# pse84 register map
Vendor: Infineon Technologies; Series: PSE84; File version: 1.0
CPU: CM33 r0p1, little endian, MPU, FPU, VTOR, 3 interrupt priority bits
Registers are 32-bit, read-write, reset 0x0 unless marked. A register's access mark holds for its fields unless they carry their own. Offsets are from the block's base; [hi:lo] are bit positions; lines under a group give offsets from that group; {n}, {i} and the like mark numbered series; 'fields as' and 'values as' point back to an identical list; <NAME> marks a mode.

## SRSS (part 2 of 3) — SRSS Core Registers
Base 0x42400000
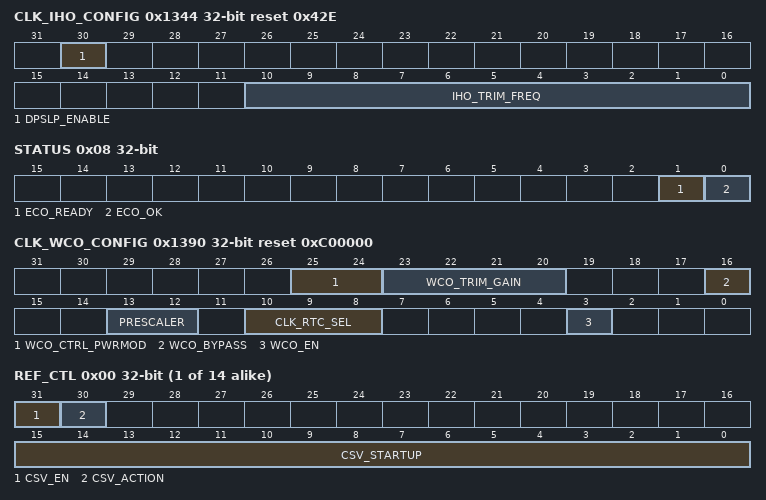
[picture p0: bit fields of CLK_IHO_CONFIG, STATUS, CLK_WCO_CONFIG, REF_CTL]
0x1344 CLK_IHO_CONFIG reset 0x42E — IHO Configuration Register
  [30] DPSLP_ENABLE — Enable for IHO during DEEPSLEEP. This bit configures IHO behavior during DEEPSLEEP: 0: IHO is automatically disabled during DEEPSLEEP and enables upon wakeup; 1: IHO is kept enabled throughout DEEPSLEEP
  [10:0] IHO_TRIM_FREQ — IHO frequency trim
0x1360 CLK_ECO group — ECO Configuration
  0x00 CONFIG — ECO Configuration Register
    [31] ECO_EN — Master enable for ECO oscillator. Configure the settings in CLK_ECO_CONFIG2 to work with the selected crystal, before enabling ECO.
    [28] ECO_DIV_ENABLE — ECO prescaler enable command (mutually exclusive with ECO_DIV_DISABLE). ECO Prescaler only works in ACTIVE and SLEEP modes. SW sets this field to '1' to enable the divider and HW sets this field to '0' to indicate that divider enabling has completed. When the divider is enabled, its integer and fractional counters are initialized to '0'. If a divider is to be re-enabled using different integer and fractional divider values, the SW should follow these steps: 0: Disable the divider using the ECO_DIV_DISABLE field. 1: Configure CLK_ECO_PRESCALE registers. 2: Enable the divider using the ECO_DIV_ENABLE field. HW sets the ECO_DIV_ENABLE field to '0' when the enabling is performed and HW set CLK_ECO_PRESCALER.ENABLED to '1' when the enabling is performed.
    [27] ECO_DIV_DISABLE — ECO prescaler disable command (mutually exclusive with ECO_DIV_ENABLE). SW sets this field to '1' and HW sets this field to '0'. HW sets ECO_DIV_DISABLE field to '0' immediately and HW sets CLK_ECO_PRESCALE.ECO_DIV_EN field to '0' immediately.
  0x04 CONFIG2 reset 0x61B — ECO Configuration Register 2
    [16] ECO_CTRL_AMPDETEN — Amplifer detect enable
    [11:8] ECO_TRIM_GAIN — Gain trim
    [4:0] ECO_TRIM_CL — Crystal load cap configuration trim
  0x08 STATUS ro — ECO Status Register
    [1] ECO_READY — Indicates the ECO internal oscillator circuit power has had enough time to fully stabilize and the CLK_EN can be set. The ECO_OK bit should be used to determine that the ECO is ready for use.
    [0] ECO_OK — Indicates the ECO internal oscillator circuit has sufficient amplitude. It may not meet the PPM accuracy or duty cycle spec.
0x1370 CLK_PILO_CONFIG reset 0x80000000 — Precision ILO Configuration Register
  [31] PILO_EN — Enable PILO. If the PILO is the selected source for WDT, writes to this field are ignored unless the WDT is unlocked using WDT_LOCK register. To save power FW must disable PILO upon entry to Hibernate if it is not used as a Hibernate clock source. PILO will continue to run in XRES if enabled.
0x1374 CLK_PILO_STATUS ro — Precision ILO Status Register
  [0] PILO_OK — Indicates the PILO is running.
0x1380 CLK_ILO_CONFIG reset 0x80000000 — ILO Configuration
  [31] ENABLE — Enable ILO. If the ILO is the selected source for WDT, writes to this field are ignored unless the WDT is unlocked using WDT_LOCK register. To save power, FW must disable ILO upon entry to Hibernate if it is not used as a Hibernate clock source. ILO will continue to run in XRES if enabled.
0x1384 CLK_TRIM_ILO_CTL reset 0x2C — ILO Trim Register
  [5:0] ILO_FTRIM — IL0 frequency trims. LSB step size is 1.5 percent (typical) of the frequency. If the ILO is the selected source for WDT, writes to this field are ignored unless the WDT is unlocked using WDT_LOCK register.
0x1390 CLK_WCO_CONFIG reset 0xC00000 — WCO Configuration Register
  [25:24] WCO_CTRL_PWRMOD
  [23:20] WCO_TRIM_GAIN — main amplifier gain control. Please use S22SRSSA_WCO_CALCULATOR to obtain appropriate value for the attached crystal. Writes to this field are ignored unless the WDT is unlocked using WDT_LOCK register
  [16] WCO_BYPASS — Configures the WCO for different board-level connections to the WCO pins. For example, this can be used to connect an external watch crystal oscillator instead of a watch crystal. In all cases, the two related GPIO pins (WCO input and output pins) must be configured as analog connections using GPIO registers, and they must be hooked at the board level as described below. Configure this field before enabling the WCO, and do not change this setting when WCO_EN=1. Also if the BAK (RTC) is the selected source for WDT, Writes to this field are ignored unless the WDT is unlocked using WDT_LOCK register. 0: Watch crystal. Connect a 32.768 kHz watch crystal between WCO input and output pins. 1: Clock signal, either a square wave or sine wave. See PRESCALER field for connection information.
  [13:12] PRESCALER
  [10:8] CLK_RTC_SEL — Clock select for RTC clock. If the BAK (RTC) is the selected source for WDT, Writes to this field are ignored unless the WDT is unlocked using WDT_LOCK register. Selecting a clock that is not running results in unpredictable behavior.
    0=WCO (Watch-crystal oscillator input, available in Active, DeepSleep and Hibernate.); 1=ALTBAK (This allows to use the LFCLK selection as an alternate backup domain clock. Note that LFCLK is only available in Active and DeepSleep power modes. Note that LFCLK clock glitches can propagate into the RTC logic when the clock is stopped. For this reason, if the WCO, PILO or ILO is intended as the clock source then choose it directly instead of routing through LFCLK.); 2=ILO (Internal Low frequency Oscillator, available in Active, DeepSleep, and Hibernate. With this option selected, ILO reset is suppressed in XRES/Hibernate modes.); 3=PILO (Precision internal low-speed oscillator, available in Active, DeepSleep, and Hibernate. With this option selected, PILO reset is suppressed in XRES/Hibernate modes.); 4=RSVD (N/A)
  [3] WCO_EN — Watch-crystal oscillator (WCO) enable. If there is an RTC write in progress and WCO is the clock source for clk_rtc when this bit is cleared, the WCO will be internally kept on until the write completes. After enabling the WCO software must wait until CLK_WCO_STATUS.WCO_OK=1 before configuring any component that depends on clk_lf/clk_rtc, like for example RTC or WDTs. If the BAK (RTC) is the selected source for WDT, writes to this field are ignored unless the WDT is unlocked using WDT_LOCK register.
0x1394 CLK_WCO_STATUS ro — WCO Status Register
  [2] WCO_OK — Indicates that output has transitioned.
0x1400 CSV_HF group — Clock Supervisor (CSV) registers for Root clocks
  {0x0+0x10*j} CSV[{j}] (j=0..13) group — Active domain Clock Supervisor (CSV) registers
    0x00 REF_CTL — Clock Supervision Reference Control
      [31] CSV_EN — Enables clock supervision, both frequency and loss. CSV in Active domain: Clock supervision is reset during DeepSleep and Hibernate modes. When enabled it begins operating automatically after a DeepSleep wakeup, but it must be reconfigured after Hibernate wakeup. CSV in DeepSleep domain: Clock supervision is reset during Hibernate mode. It must be reconfigured after Hibernate wakeup. A CSV error detection is reported to the Fault structure, or instead it can generate a power reset.
      [30] CSV_ACTION — Specifies the action taken when an anomaly is detected on the monitored clock. CSV in DeepSleep domain always do a Fault report (which also wakes up the system).
        0=FAULT (Generate a fault); 1=RESET (Cause a power reset. This should only be used for clk_hf0.)
      [15:0] CSV_STARTUP — Startup delay time -1 (in reference clock cycles), after enable or DeepSleep wakeup, from reference clock start to monitored clock start. At a minimum (both clocks running): STARTUP >= (PERIOD +3) * FREQ_RATIO - UPPER, with FREQ_RATIO = (Reference frequency / Monitored frequency) On top of that the actual clock startup delay and the margin for accuracy of both clocks must be added.
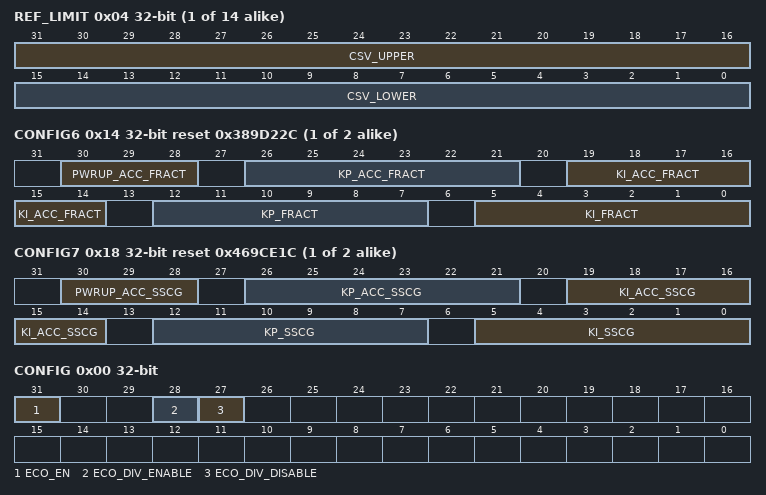
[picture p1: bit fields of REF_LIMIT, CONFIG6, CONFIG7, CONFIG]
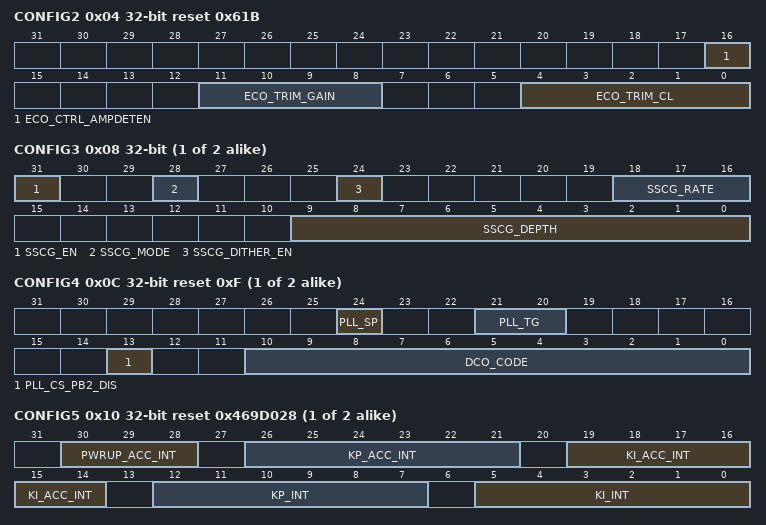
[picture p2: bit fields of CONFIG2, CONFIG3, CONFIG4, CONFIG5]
    0x04 REF_LIMIT — Clock Supervision Reference Limits
      [31:16] CSV_UPPER — Cycle time upper limit. Set the upper limit -1, in reference clock cycles, before (or same time) the next monitored clock event must happen. If a monitored clock event does not happen before this limit is reached, or does not happen at all (clock loss), a CSV error is detected.
      [15:0] CSV_LOWER — Cycle time lower limit. Set the lower limit -1, in reference clock cycles, before the next monitored clock event is allowed to happen. If a monitored clock event happens before this limit is reached a CSV error is detected. LOWER must be at least 1 less than UPPER. In case the clocks are asynchronous LOWER must be at least 3 less than UPPER.
    0x08 MON_CTL — Clock Supervision Monitor Control
      [15:0] CSV_PERIOD — Period time. Set the Period -1, in monitored clock cycles, before the next monitored clock event happens. PERIOD <= (UPPER+1) / FREQ_RATIO -1, with FREQ_RATIO = (Reference frequency / Monitored frequency) In case the clocks are asynchronous: PERIOD <= UPPER / FREQ_RATIO -1 Additionally margin must be added for accuracy of both clocks.
0x1500 CSV_REF_SEL reset 0x4 — Select CSV Reference clock for Active domain
  [2:0] REF_MUX — Selects a source for clock clk_ref_hf. Note that not all products support all clock sources. Selecting a clock source that is not supported will result in undefined behavior. It takes four cycles of the originally selected clock to switch away from it. Do not disable the original clock during this time.
    0=IMO (IMO - Internal R/C Oscillator (product specific)); 1=EXTCLK (EXTCLK - External Clock Pin); 2=ECO (ECO - External-Crystal Oscillator); 3=ALTHF0 (ALTHF0 - Alternate High-Frequency clock input (product-specific clock)); 4=IHO (IHO - Internal High-speed Oscillator); 5=ALTHF1 (ALTHF1 - Alternate High-Frequency clock input (product-specific clock))
0x1510 CSV_REF group — CSV registers for the CSV Reference clock
  0x00 CSV group — Active domain Clock Supervisor (CSV) registers for CSV Reference clock
    0x00 REF_CTL — Clock Supervision Reference Control
      fields as CSV_HF.CSV[0].REF_CTL
    0x04 REF_LIMIT — Clock Supervision Reference Limits
      fields as CSV_HF.CSV[0].REF_LIMIT
    0x08 MON_CTL — Clock Supervision Monitor Control
      fields as CSV_HF.CSV[0].MON_CTL
0x1520 CSV_LF_REF_SEL — Select CSV Reference clock for LF clock
  [1:0] LF_REF_MUX — Selects a source for clock clk_ref_lf. Note that not all products support all clock sources. Selecting a clock source that is not supported will result in undefined behavior. It takes four cycles of the originally selected clock to switch away from it. Do not disable the original clock during this time. Same clcok sources are also souce for clk_lf. Do not select the same clock.
    0=PILO (Precision internal low-speed oscillator, available in Active, DeepSleep, and Hibernate. (Product Specific)); 1=ILO (Internal Low frequency Oscillator, available in Active, DeepSleep, and Hibernate. (Product Specific)); 2=WCO (Watch-crystal oscillator input, available in Active, DeepSleep, and Hibernate. (Product Specific)); 3=TIMERCLK (Timer clock. Divided clock from IHO set to 1MHz. Available only during Active mode. If this clock is selected as reference, CSV will be disabled by hardware when entering lower power modes (DPSLP) and re-enabled back in Active.)
0x1530 CSV_LF group — CSV registers for LF clock
  0x00 CSV group — LF clock Clock Supervisor registers
    0x00 REF_CTL — Clock Supervision Reference Control
      [31] CSV_EN — Enables clock supervision, both frequency and loss. CSV in Active domain: Clock supervision is reset during DeepSleep and Hibernate modes. When enabled it begins operating automatically after a DeepSleep wakeup, but it must be reconfigured after Hibernate wakeup. CSV in DeepSleep domain: Clock supervision is reset during Hibernate mode. It must be reconfigured after Hibernate wakeup. CSV in Backup domain: Clock supervision operates during Hibernate mode, can be configured to wake from Hibernate, and continues operating during reboot. A CSV error detection is reported to the Fault structure.
      [7:0] CSV_STARTUP — Startup delay time -1 (in reference clock cycles), after enable, from reference clock start to monitored clock start. At a minimum (both clocks running): STARTUP >= (PERIOD +3) * FREQ_RATIO - UPPER, with FREQ_RATIO = (Reference frequency / Monitored frequency) On top of that the actual clock startup delay and the margin for accuracy of both clocks must be added.
    0x04 REF_LIMIT — Clock Supervision Reference Limits
      [23:16] CSV_UPPER — Cycle time upper limit. Set the upper limit -1, in reference clock cycles, before (or same time) the next monitored clock event must happen. If a monitored clock event does not happen before this limit is reached, or does not happen at all (clock loss), a CSV error is detected.
      [7:0] CSV_LOWER — Cycle time lower limit. Set the lower limit -1, in reference clock cycles, before the next monitored clock event is allowed to happen. If a monitored clock event happens before this limit is reached a CSV error is detected. LOWER must be at least 1 less than UPPER. In case the clocks are asynchronous LOWER must be at least 3 less than UPPER.
    0x08 MON_CTL — Clock Supervision Monitor Control
      [7:0] CSV_PERIOD — Period time. Set the Period -1, in monitored clock cycles, before the next monitored clock event happens. PERIOD <= (UPPER+1) / FREQ_RATIO -1, with FREQ_RATIO = (Reference frequency / Monitored frequency) In case the clocks are asynchronous: PERIOD <= UPPER / FREQ_RATIO -1 Additionally margin must be added for accuracy of both clocks.
0x1540 CSV_PILO_REF_SEL — Select CSV Reference clock for PILO clock
  [1:0] PILO_REF_MUX — Selects a source for clock clk_ref_pilo. Note that not all products support all clock sources. Selecting a clock source that is not supported will result in undefined behavior. It takes four cycles of the originally selected clock to switch away from it. Do not disable the original clock during this time. PILO is a source for clk_lf. Do not select LF when LF clock is using PILO.
    0=LFCLK (Root of the low-speed clock tree (LFCLK)); 1=ILO (Internal Low frequency Oscillator, available in Active, DeepSleep, and Hibernate. (Product Specific)); 2=WCO (Watch-crystal oscillator input, available in Active, DeepSleep, and Hibernate. (Product Specific)); 3=TIMERCLK (Timer clock. Divided clock from IHO set to 1MHz. Available only during Active mode. If this clock is selected as reference, CSV will be disabled by hardware when entering lower power modes (DPSLP) and re-enabled back in Active.)
{0x1600+0x20*i} CLK_DPLL_LP[{i}] (i=0..1) group — DPLL LP Configuration Register
  0x00 CONFIG reset 0x20116 — DPLL_LP Configuration Register
    [31] ENABLE — Master enable for PLL. Setup FEEDBACK_DIV, REFERENCE_DIV, and OUTPUT_DIV at least one cycle before setting ENABLE=1. fOUT = (FEEDBACK_DIV + FRAC_EN*FRAC_DIV/2^24) * (fREF / REFERENCE_DIV) / (OUTPUT_DIV) 0: Block is disabled. When the PLL disables, hardware controls the bypass mux as described in BYPASS_SEL, before disabling the PLL circuit. 1: Block is enabled
    [29:28] BYPASS_SEL — Bypass mux located just after PLL output. This selection is glitch-free and can be changed while the PLL is running. When changing BYPASS_SEL, do not turn off the reference clock or PLL clock for five cycles (whichever is slower).
      0=AUTO (Automatic using lock indicator. When unlocked, automatically selects PLL reference input (bypass mode). When locked, automatically selects PLL output. If ENABLE=0, automatically selects PLL reference input.); 1=LOCKED_OR_NOTHING (Similar to AUTO, except the clock is gated off when unlocked. This is compatible with clock supervision, because the supervisors allow no clock during startup (until a timeout occurs), and the clock targets the proper frequency whenever it is running. If ENABLE=0, no clock is output.); 2=PLL_BYPASS (Select PLL reference input (bypass mode). Ignores lock indicator); 3=PLL_OUT (Select PLL output. Ignores lock indicator. If ENABLE=0, no clock is output.)
    [27] PLL_DCO_MODE — dco_mode='0' DCO freq 160-310MHz , '1' - DCO freq 310-480MHz
    [20:16] OUTPUT_DIV — Control bits for Output divider. Set the divide value before enabling the PLL, and do not change it while PLL is enabled. 0: illegal (undefined behavior) 1: divide by 1. Suitable for direct usage as HFCLK source. 2: divide by 2. Suitable for direct usage as HFCLK source. ... 16: divide by 16. Suitable for direct usage as HFCLK source. >16: illegal (undefined behavior)
    [12:8] REFERENCE_DIV — Control bits for reference divider. Set the divide value before enabling the PLL, and do not change it while PLL is enabled. 0: illegal (undefined behavior) 1: divide by 1 ... 16: divide by 16 others: illegal (undefined behavior)
    [7:0] FEEDBACK_DIV — Control bits for feedback divider. Set the divide value before enabling the PLL, and do not change it while PLL is enabled. 0-15: illegal (undefined behavior) 16: divide by 16 ... 200: divide by 200 >200: illegal (undefined behavior)
  0x04 CONFIG2 — DPLL_LP Configuration Register 2
    [31] FRAC_EN — Enables fractional division mode.
    [30:28] FRAC_DITHER_EN
    [23:0] FRAC_DIV — Control bits for fractional divider. This value is interpreted as a fraction of the PFD frequency, i.e. fPFD * (FRAC_DIV/2^24). This field can be dynamically updated within the 1000ppm control limit. It takes up to 115 AHB cycles to transfer the setting to the PLL, and writes that occur faster may be silently ignored and require the application to write again after the previous update has finished. Reading the register returns the accepted value. The PLL will start targeting the new value, but it may take significant time (milliseconds) to stabilize at the new average value. Do not change the FRAC_DIV setting while the PLL is initially locking.
  0x08 CONFIG3 — DPLL_LP Configuration Register 3
    [31] SSCG_EN — Enables spreading mode. When SSCG mode is enabled, DPLL_LP_TEST4.PLL_DIS_FAST_LOCK should be set to 1 to disable fast re-lock.
    [28] SSCG_MODE
    [24] SSCG_DITHER_EN
    [18:16] SSCG_RATE
    [9:0] SSCG_DEPTH
  0x0C CONFIG4 reset 0xF — DPLL_LP Configuration Register 4
    [24] PLL_SP
    [21:20] PLL_TG — This value is a number of PFD clocks in relation to the DCO count. Can change the number of counts, set by p_div in integer mode, by the values of -1, +1, or +2. 0: 0 1: -1 2: +1 3: +2 In integer and SSCG mode, PLL_TG must be set to 0. If in fractional mode, PLL_TG must be 0 if frac_ratio <= 0.5 (pll_frac <= 2^23), PLL_TG must be 2 if frac_ratio > 0.5 (pll_frac > 2^23).
    [13] PLL_CS_PB2_DIS — disable internal bias
    [10:0] DCO_CODE — Initial DCO code. It is recommended to leave this at the default setting. This setting only has effect in open loop mode. See DPLL BROS regarding test modes.
  0x10 CONFIG5 reset 0x469D028 — DPLL_LP Configuration Register 5
    [30:28] PWRUP_ACC_INT — Power Up Accleration Coefficient for INT operation
    [26:21] KP_ACC_INT — Gain of P/I loop filter integrator path during cold start for INT operation. Gain coefficient is 2^KP, eg. 0=>1, 15=>32768.
    [19:14] KI_ACC_INT — Gain of P/I loop filter integrator path during cold start for INT operation. Gain coefficient is 2^KI, eg. 0=>1, 15=>32768.
    [12:7] KP_INT — Gain of P/I loop filter integrator path for INT operation. Gain coefficient is 2^KP, eg. 0=>1, 15=>32768.
    [5:0] KI_INT — Gain of P/I loop filter integrator path for INT operation. Gain coefficient is 2^KI, eg. 0=>1, 15=>32768.
  0x14 CONFIG6 reset 0x389D22C — DPLL_LP Configuration Register 6
    [30:28] PWRUP_ACC_FRACT — Power Up Accleration Coefficient for FRACT operation
    [26:21] KP_ACC_FRACT — Gain of P/I loop filter integrator path during cold start for FRACT operation. Gain coefficient is 2^KP, eg. 0=>1, 15=>32768.
    [19:14] KI_ACC_FRACT — Gain of P/I loop filter integrator path during cold start for FRACT operation. Gain coefficient is 2^KI, eg. 0=>1, 15=>32768.
    [12:7] KP_FRACT — Gain of P/I loop filter proportional path for FRACT operation. Gain coefficient is 2^KP, eg. 0=>1, 15=>32768.
    [5:0] KI_FRACT — Gain of P/I loop filter proportional path for FRACT operation. Gain coefficient is 2^KI, eg. 0=>1, 15=>32768.
  0x18 CONFIG7 reset 0x469CE1C — DPLL_LP Configuration Register 7
    [30:28] PWRUP_ACC_SSCG — Power Up Accleration Coefficient for SSCG operation
    [26:21] KP_ACC_SSCG — Gain of P/I loop filter integrator path during cold start for SSCG operation. Gain coefficient is 2^KP, eg. 0=>1, 15=>32768.
    [19:14] KI_ACC_SSCG — Gain of P/I loop filter integrator path during cold start for SSCG operation. Gain coefficient is 2^KI, eg. 0=>1, 15=>32768.
    [12:7] KP_SSCG — Gain of P/I loop filter proportional path for SSCG operation. Gain coefficient is 2^KP, eg. 0=>1, 15=>32768.
    [5:0] KI_SSCG — Gain of P/I loop filter proportional path for SSCG operation. Gain coefficient is 2^KI, eg. 0=>1, 15=>32768.
  0x1C STATUS — DPLL_LP Status Register
    [1] UNLOCK_OCCURRED — This bit sets whenever the PLL Lock bit goes low, and stays set until cleared by firmware. Note: When disabling DPLL via register write, UNLOCK_OCCURRED will set. Therefore, after enabling DPLL and DPLL successfully locks, FW should clear UNLOCK_OCCURRED flag to prevent a false positive that would indicate that DPLL erroneously unlocked.
    [0] LOCKED ro — PLL Lock Indicator
0x1800 CLK_DPLL_HP group — DPLL HP Configuration Register
  0x00 CONFIG reset 0x1013 — DPLL_HP Configuration Register
    [31] ENABLE — Master enable for PLL. Setup PLL for integer, fract or SCSG at least one cycle before setting ENABLE=1. 0: Block is disabled. When the PLL disables, hardware controls the bypass mux as described in BYPASS_SEL, before disabling the PLL circuit. 1: Block is enabled
    [29:28] BYPASS_SEL — Bypass mux located just after PLL output. This selection is glitch-free and can be changed while the PLL is running. When changing BYPASS_SEL, do not turn off the reference clock or PLL clock for five cycles (whichever is slower).
      values as CLK_DPLL_LP[0].CONFIG.BYPASS_SEL
    [14:12] PLL_FREQ_KDIV_SEL — K-divider division factor (K = kdiv_sel_i + 1 )
    [10:8] PLL_FREQ_PDIV_SEL — P-divider division factor (P = pdiv_sel_i + 1 ) (Cannot be changed on the fly when the PLL is enabled)
    [7:0] PLL_FREQ_NDIV_INT_SEL — N-divider division factor (N = ndiv_sel_i + 1 ) (Cannot be changed on the fly when the PLL is enabled)
  0x04 CONFIG2 reset 0x8E00000 — DPLL_HP Configuration Register 2
    [27:24] PLL_IVR_TRIM — control word for trimming the regulated voltage that is internally generated from the 1v8 supply (default value = '10') (Cannot be changed on the fly when the PLL is enabled)
    [23:21] PLL_FREQ_MODE_SEL — selects the waiting time for Power Initialization sequence, based on the PLL running frequency (Cannot be changed on the fly when the PLL is enabled)
    [20:0] PLL_FREQ_NDIV_FRACT_SEL — N-divider division factor (N = ndiv_sel_i + 1) (Cannot be changed on the fly when the PLL is enabled)
  0x08 CONFIG3 reset 0x1 — DPLL_HP Configuration Register 3
    [29] PLL_FDSM_SEL — DSM clock division select (Cannot be changed on the fly when the PLL is enabled)
      0=DIV_BY_4 (Divide output by 4); 1=DIV_BY_2 (Divide output by 2)
    [0] PLL_CLKR_SEL — Select retimed reference clock (Cannot be changed on the fly when the PLL is enabled)
  0x0C CONFIG4 reset 0x27618AC — DPLL_HP Configuration Register 4
    [30:27] PLL_FLOCK_OBSWIN — Period over which PQDIFF is computed/observed. If 0 = use HW computed window. Supported values: 0-4 and 8 (Cannot be changed on the fly when the PLL is enabled)
    [26:23] PLL_FLOCK_LK_WAITPER — Period over which flock_en_thresh must be met in order for Freq Locking. Supported values: 0-8 (Cannot be changed on the fly when the PLL is enabled)
    [22:20] PLL_FLOCK_LK_THRESH — PQDIFF threshold under which DLL asserts Freq LOCK (Cannot be changed on the fly when the PLL is enabled)
    [19:16] PLL_FLOCK_WAITPER — Period over which flock_en_thresh must be met in order for FINE Filtering enabling. Supported values: 0-8 (Cannot be changed on the fly when the PLL is enabled)
    [13:11] PLL_FLOCK_EN_THRESH — PQDIFF threshold under which FINE Filtering gets enabled (Cannot be changed on the fly when the PLL is enabled) CONFIG.PLL_FREQ_NDIV_INT_SEL >= 20 -> PLL_FLOCK_EN_THRESH == 0x7; CONFIG.PLL_FREQ_NDIV_INT_SEL < 20 -> PLL_FLOCK_EN_THRESH == 0x3;
    [9:5] PLL_LF_LC_BETA — Beta value of the coarse filter (Cannot be changed on the fly when the PLL is enabled)
    [4:0] PLL_LF_LC_ALPHA — Alpha value of the coarse filter (Cannot be changed on the fly when the PLL is enabled)
  0x10 CONFIG5 reset 0x1294 — DPLL_HP Configuration Register 5
    [28:16] PLL_DT_CAL_DIG ro — FW should read pll_dutycal_dig_o only when pll_dutycal_ok is high to know the status of DUTY CAL circuit.
    [12] PLL_LF_SET_PARAMS — enable for external loop filter control (alpha and beta values) (Cannot be changed on the fly when the PLL is enabled)
    [9:5] PLL_LF_BETA — External beta value (Cannot be changed on the fly when the PLL is enabled) Fref/(pdiv_sel_i+1) >= 25MHz -> PLL_LF_BETA == 0x14 Fref/(pdiv_sel_i+1) < 25MHz -> PLL_LF_BETA == 0x10
    [4:0] PLL_LF_ALPHA — External alpha value (Cannot be changed on the fly when the PLL is enabled)
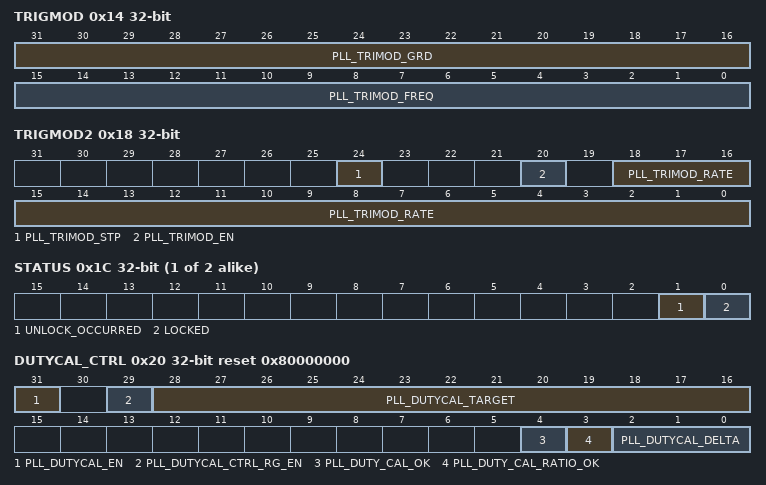
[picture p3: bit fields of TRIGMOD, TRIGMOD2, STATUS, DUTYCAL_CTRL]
  0x14 TRIGMOD — DPLL_HP Trigmod SSCG Register
    [31:16] PLL_TRIMOD_GRD — Triangular-Frequency Modulation: modulation gradient. See formula in the BROS (word file) (Can be changed when PLL is enabled but cannot be changed on the fly when pll_trimod_en_i=1)
    [15:0] PLL_TRIMOD_FREQ — Triangular-Frequency Modulation: modulation frequency. See formula in the BROS (word file) (Can be changed when PLL is enabled but cannot be changed on the fly when pll_trimod_en_i=1)
  0x18 TRIGMOD2 — DPLL_HP Trigmod2 SSCG Register
    [24] PLL_TRIMOD_STP — Triangular-Frequency Modulation stop
    [20] PLL_TRIMOD_EN — Triangular-Frequency Modulation enable
    [18:0] PLL_TRIMOD_RATE — triangular frequency modulation: trimod_rate = mod_grad_i * 16/mod_freq_i (Cannot be changed on the fly when the PLL is enabled)
  0x1C STATUS — DPLL_HP Status Register
    [20] PLL_LOCKDET_RES_ACK ro — acknowledgement for lock detection restart
    [16] PLL_LOCKDET_RES — Restart lock detector
    [1] UNLOCK_OCCURRED — This bit sets whenever the PLL Lock bit goes low, and stays set until cleared by firmware.
    [0] LOCKED ro — PLL Lock Indicator
  0x20 DUTYCAL_CTRL reset 0x80000000 — DPLL_HP_User DUTYCAL Control Register
    [31] PLL_DUTYCAL_EN — dutycal: enables duty cycle calibration (Cannot be changed on the fly when the PLL is enabled)
    [29] PLL_DUTYCAL_CTRL_RG_EN — dutycal: enables ring oscillator for duty cycle digitization (Cannot be changed on the fly when the PLL is enabled)
    [28:16] PLL_DUTYCAL_TARGET — duty cycle target (Cannot be changed on the fly when the PLL is enabled)
    [4] PLL_DUTY_CAL_OK ro — Status of the duty calibration ok
    [3] PLL_DUTY_CAL_RATIO_OK ro — Status of the duty calibration ratio ok
    [2:0] PLL_DUTYCAL_DELTA — dutycal: margins for the duty cycle calibration error (Cannot be changed on the fly when the PLL is enabled)
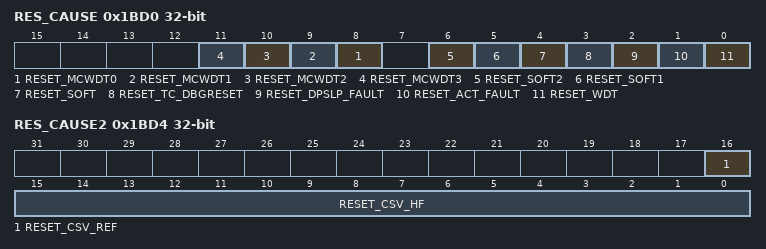
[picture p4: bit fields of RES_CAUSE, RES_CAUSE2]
0x1BD0 RES_CAUSE — Reset Cause Observation Register
  [n+8] RESET_MCWDT{n} (n=0..3) — Multi-Counter Watchdog timer reset #{n}. This is a low-voltage cause bit that hardware clears when the low-voltage supply is initialized (see comments above).
  [6] RESET_SOFT2 — CPU[2] requested a system reset through it's SYSRESETREQ. This can be done via a debugger probe or in firmware. This is a low-voltage cause bit that hardware clears when the low-voltage supply is initialized (see comments above).
  [5] RESET_SOFT1 — CPU[1] requested a system reset through it's SYSRESETREQ. This can be done via a debugger probe or in firmware. This is a low-voltage cause bit that hardware clears when the low-voltage supply is initialized (see comments above).
  [4] RESET_SOFT — CPU[0] requested a system reset through it's SYSRESETREQ. This can be done via a debugger probe or in firmware. This is a low-voltage cause bit that hardware clears when the low-voltage supply is initialized (see comments above).
  [3] RESET_TC_DBGRESET — Test controller or debugger asserted reset. This asserts low-voltage resets including the debug domain. This is a low-voltage cause bit that hardware clears when the low-voltage supply is initialized (see comments above).
  [2] RESET_DPSLP_FAULT
  [1] RESET_ACT_FAULT — Fault logging system requested a reset from its Active logic. This is a low-voltage cause bit that hardware clears when the low-voltage supply is initialized (see comments above).
  [0] RESET_WDT — A basic WatchDog Timer (WDT) reset has occurred since last power cycle. ULP products: This is a low-voltage cause bit that hardware clears when the low-voltage supply is initialized (see comments above). For products that support high-voltage cause detection, this bit blocks recording of other high-voltage cause bits, except RESET_PORVDDD, or *XRES. Hardware clears this bit during POR. This bit is not blocked by other HV cause bits.
0x1BD4 RES_CAUSE2 — Reset Cause Observation Register 2
  [16] RESET_CSV_REF — Clock supervision logic requested a reset due to loss or frequency violation of the reference clock source that is used to monitor the other HF clock sources.
  [15:0] RESET_CSV_HF — Clock supervision logic requested a reset due to loss or frequency violation of a high-frequency clock. Each bit index K corresponds to a HFCLK<K>. Unimplemented clock bits return zero.
0x1BE4 RES_PXRES_CTL wo — Programmable XRES Control Register
  [0] PXRES_TRIGGER — Triggers PXRES. This causes a full-scope reset and reboot.

## Notices in the file
(c) 2016-2026, Infineon Technologies AG or an affiliate of
Infineon Technologies AG.
SPDX-License-Identifier: Apache-2.0
Licensed under the Apache License, Version 2.0 (the "License");
you may not use this file except in compliance with the License.
You may obtain a copy of the License at
http://www.apache.org/licenses/LICENSE-2.0
Unless required by applicable law or agreed to in writing, software
distributed under the License is distributed on an "AS IS" BASIS,
WITHOUT WARRANTIES OR CONDITIONS OF ANY KIND, either express or implied.
See the License for the specific language governing permissions and
limitations under the License.
